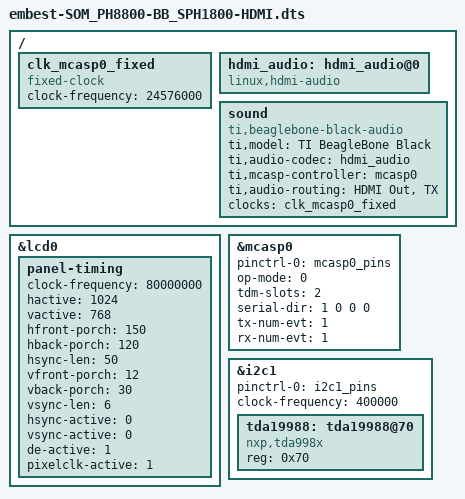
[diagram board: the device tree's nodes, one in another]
/*
 * Copyright (C) 2015 Embest Technology Co., Ltd., - http://www.embest-tech.com
 *
 * This program is free software; you can redistribute it and/or modify
 * it under the terms of the GNU General Public License version 2 as
 * published by the Free Software Foundation.
 *
 * This dts is for embest own product:
 * SOM-PH8800 + BB-SPH1800
 */
/*/dts-v1/;*/

#include "embest-SOM_PH8800-BB_SPH1800.dts"

/ {

	clk_mcasp0_fixed: clk_mcasp0_fixed {
	      #clock-cells = <0>;
	      compatible = "fixed-clock";
	      clock-frequency = <24576000>;
	};

	/*clk_mcasp0: clk_mcasp0 {
	      #clock-cells = <0>;
	      compatible = "gpio-gate-clock";
	      clocks = <&clk_mcasp0_fixed>;
	      enable-gpios = <&gpio1 27 1>; 
	};*/

	hdmi_audio: hdmi_audio@0 {
		#sound-dai-cells = <0>;
		compatible = "linux,hdmi-audio";
		status = "okay";
	};

	sound {
		compatible = "ti,beaglebone-black-audio";
		ti,model = "TI BeagleBone Black";
		ti,audio-codec = <&hdmi_audio>;
		ti,mcasp-controller = <&mcasp0>;
		ti,audio-routing =
			"HDMI Out",	"TX";
		clocks = <&clk_mcasp0_fixed>;
		clock-names = "mclk";
	};
};

&lcd0{
	panel-timing {
		/*This is the timing for HDMI&VGA*/
		clock-frequency = <80000000>;
		hactive = <1024>;
		vactive = <768>;
		hfront-porch = <150>;
		hback-porch = <120>;
		hsync-len = <50>;
		vfront-porch = <12>;
		vback-porch = <30>;
		vsync-len = <6>;
		hsync-active = <0>;
		vsync-active = <0>;
		de-active = <1>;
		pixelclk-active = <1>;
	};
};


&mcasp0	{
	#sound-dai-cells = <0>;
	pinctrl-names = "default";
	pinctrl-0 = <&mcasp0_pins>;
	status = "okay";
	op-mode = <0>;	/* MCASP_IIS_MODE */
	tdm-slots = <2>;
	serial-dir = <	/* 0: INACTIVE, 1: TX, 2: RX */
			1 0 0 0
		>;
	tx-num-evt = <1>;
	rx-num-evt = <1>;
};


&i2c1 {
	status = "okay";
	pinctrl-names = "default";
	pinctrl-0 = <&i2c1_pins>;
	clock-frequency = <400000>;

	tda19988: tda19988@70 {
		compatible = "nxp,tda998x";
		reg = <0x70>;
		
	};
};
